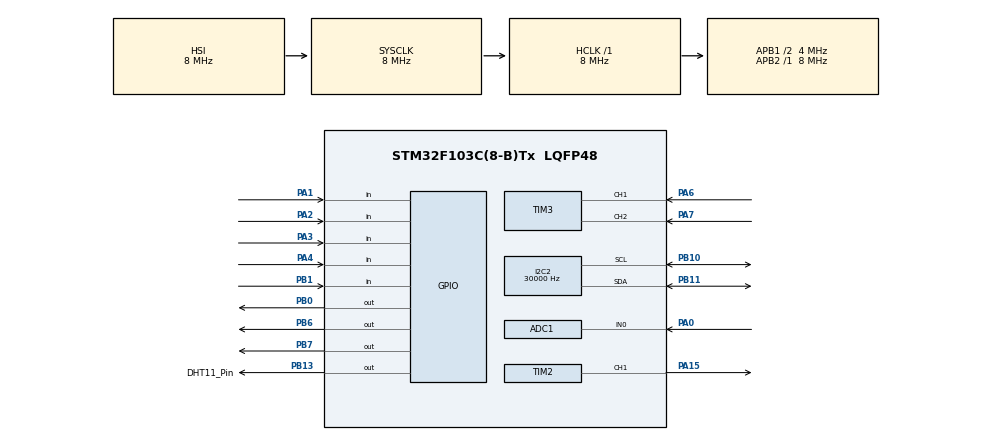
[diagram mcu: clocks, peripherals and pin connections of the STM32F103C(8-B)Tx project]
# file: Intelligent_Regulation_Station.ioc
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ADC1.Channel-2\#ChannelRegularConversion=ADC_CHANNEL_0
ADC1.EnableInjectedConversion=ENABLE
ADC1.InjNumberOfConversion=0
ADC1.NbrOfConversion=1
ADC1.NbrOfConversionFlag=1
ADC1.Rank-2\#ChannelRegularConversion=1
ADC1.SamplingTime-2\#ChannelRegularConversion=ADC_SAMPLETIME_1CYCLE_5
ADC1.master=1
FREERTOS.Tasks01=OLED_Task,8,512,Start_OLED_Task,As weak,NULL,Dynamic,NULL,NULL;air_sensor_Task,16,384,Start_air_sensor_Task,As weak,NULL,Dynamic,NULL,NULL;dht11_Task,16,384,Start_dht_Task,As weak,NULL,Dynamic,NULL,NULL;key_Task,40,256,Start_key_Task,As weak,NULL,Dynamic,NULL,NULL;encoder_Task,32,256,Start_encoder_Task,As weak,NULL,Dynamic,NULL,NULL;Battery_Task,8,256,Start_Battery_Task,As weak,NULL,Dynamic,NULL,NULL
FREERTOS.configTOTAL_HEAP_SIZE=12288
I2C2.ClockSpeed=30000
Mcu.Family=STM32F1
Mcu.Name=STM32F103C(8-B)Tx
Mcu.Package=LQFP48
NVIC.PriorityGroup=NVIC_PRIORITYGROUP_4
NVIC.TIM1_UP_IRQn=true\:15\:0\:false\:false\:true\:false\:false\:true\:true
NVIC.TimeBase=TIM1_UP_IRQn
NVIC.TimeBaseIP=TIM1
PA0-WKUP.GPIO_Mode=GPIO_MODE_ANALOG
PA0-WKUP.Signal=SharedAnalog_PA0
PA1.GPIO_Mode=GPIO_MODE_INPUT
PA1.GPIO_PuPd=GPIO_PULLUP
PA1.Signal=GPIO_Input
PA13.Mode=Serial_Wire
PA13.Signal=SYS_JTMS-SWDIO
PA14.Mode=Serial_Wire
PA14.Signal=SYS_JTCK-SWCLK
PA15.Signal=S_TIM2_CH1_ETR
PA2.GPIO_Mode=GPIO_MODE_INPUT
PA2.GPIO_PuPd=GPIO_PULLUP
PA2.Signal=GPIO_Input
PA3.GPIO_Mode=GPIO_MODE_INPUT
PA3.GPIO_PuPd=GPIO_PULLUP
PA3.Signal=GPIO_Input
PA4.GPIO_Mode=GPIO_MODE_INPUT
PA4.GPIO_PuPd=GPIO_PULLUP
PA4.Signal=GPIO_Input
PA6.Signal=S_TIM3_CH1
PA7.Signal=S_TIM3_CH2
PB0.Signal=GPIO_Output
PB1.GPIO_PuPd=GPIO_PULLUP
PB1.Signal=GPIO_Input
PB10.Mode=I2C
PB10.Signal=I2C2_SCL
PB11.Mode=I2C
PB11.Signal=I2C2_SDA
PB13.GPIO_Label=DHT11_Pin
PB13.GPIO_ModeDefaultOutputPP=GPIO_MODE_OUTPUT_PP
PB13.GPIO_PuPd=GPIO_NOPULL
PB13.Signal=GPIO_Output
PB6.PinState=GPIO_PIN_RESET
PB6.Signal=GPIO_Output
PB7.PinState=GPIO_PIN_RESET
PB7.Signal=GPIO_Output
PD0-OSC_IN.Mode=HSE-External-Oscillator
PD0-OSC_IN.Signal=RCC_OSC_IN
PD1-OSC_OUT.Mode=HSE-External-Oscillator
PD1-OSC_OUT.Signal=RCC_OSC_OUT
ProjectManager.HeapSize=0x200
ProjectManager.StackSize=0x400
ProjectManager.TargetToolchain=CMake
RCC.ADCPresc=RCC_ADCPCLK2_DIV6
RCC.AHBFreq_Value=8000000
RCC.APB1CLKDivider=RCC_HCLK_DIV2
RCC.APB1Freq_Value=4000000
RCC.APB1TimFreq_Value=8000000
RCC.APB2Freq_Value=8000000
RCC.APB2TimFreq_Value=8000000
RCC.HCLKFreq_Value=8000000
RCC.PLLMUL=RCC_PLL_MUL9
RCC.SYSCLKFreq_VALUE=8000000
RCC.USBFreq_Value=36000000
SH.S_TIM2_CH1_ETR.0=TIM2_CH1,PWM Generation1 CH1
SH.S_TIM3_CH1.0=TIM3_CH1,Encoder_Interface
SH.S_TIM3_CH2.0=TIM3_CH2,Encoder_Interface
SH.SharedAnalog_PA0.0=GPIO_Analog
SH.SharedAnalog_PA0.1=ADC1_IN0,IN0
TIM2.AutoReloadPreload=TIM_AUTORELOAD_PRELOAD_ENABLE
TIM2.Channel-PWM\ Generation1\ CH1=TIM_CHANNEL_1
TIM2.Period=999
TIM2.Prescaler=71
TIM3.AutoReloadPreload=TIM_AUTORELOAD_PRELOAD_ENABLE
TIM3.EncoderMode=TIM_ENCODERMODE_TI12
TIM4.Prescaler=71
VP_FREERTOS_VS_CMSIS_V2.Mode=CMSIS_V2
VP_SYS_VS_tim1.Mode=TIM1
VP_TIM2_VS_ClockSourceINT.Mode=Internal
VP_TIM4_VS_ClockSourceINT.Mode=Internal
board=custom

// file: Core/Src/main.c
/* USER CODE BEGIN Header */
/**
  ******************************************************************************
  * @file           : main.c
  * @brief          : Main program body
  ******************************************************************************
  * @attention
  *
  * Copyright (c) 2026 STMicroelectronics.
  * All rights reserved.
  *
  * This software is licensed under terms that can be found in the LICENSE file
  * in the root directory of this software component.
  * If no LICENSE file comes with this software, it is provided AS-IS.
  *
  ******************************************************************************
  */
/* USER CODE END Header */
#include "main.h"
#include "cmsis_os.h"

ADC_HandleTypeDef hadc1;

I2C_HandleTypeDef hi2c2;

TIM_HandleTypeDef htim2;
TIM_HandleTypeDef htim3;
TIM_HandleTypeDef htim4;

/* Definitions for OLED_Task */
osThreadId_t OLED_TaskHandle;
const osThreadAttr_t OLED_Task_attributes = {
  .name = "OLED_Task",
  .stack_size = 512 * 4,
  .priority = (osPriority_t) osPriorityLow,
};
/* Definitions for air_sensor_Task */
osThreadId_t air_sensor_TaskHandle;
const osThreadAttr_t air_sensor_Task_attributes = {
  .name = "air_sensor_Task",
  .stack_size = 384 * 4,
  .priority = (osPriority_t) osPriorityBelowNormal,
};
/* Definitions for dht11_Task */
osThreadId_t dht11_TaskHandle;
const osThreadAttr_t dht11_Task_attributes = {
  .name = "dht11_Task",
  .stack_size = 384 * 4,
  .priority = (osPriority_t) osPriorityBelowNormal,
};
/* Definitions for key_Task */
osThreadId_t key_TaskHandle;
const osThreadAttr_t key_Task_attributes = {
  .name = "key_Task",
  .stack_size = 256 * 4,
  .priority = (osPriority_t) osPriorityHigh,
};
/* Definitions for encoder_Task */
osThreadId_t encoder_TaskHandle;
const osThreadAttr_t encoder_Task_attributes = {
  .name = "encoder_Task",
  .stack_size = 256 * 4,
  .priority = (osPriority_t) osPriorityAboveNormal,
};
/* Definitions for Battery_Task */
osThreadId_t Battery_TaskHandle;
const osThreadAttr_t Battery_Task_attributes = {
  .name = "Battery_Task",
  .stack_size = 256 * 4,
  .priority = (osPriority_t) osPriorityLow,
};

void SystemClock_Config(void);
static void MX_GPIO_Init(void);
static void MX_ADC1_Init(void);
static void MX_I2C2_Init(void);
static void MX_TIM2_Init(void);
static void MX_TIM3_Init(void);
static void MX_TIM4_Init(void);
void Start_OLED_Task(void *argument);
void Start_air_sensor_Task(void *argument);
void Start_dht_Task(void *argument);
void Start_key_Task(void *argument);
void Start_encoder_Task(void *argument);
void Start_Battery_Task(void *argument);

int main(void)
{

  /* MCU Configuration--------------------------------------------------------*/

  /* Reset of all peripherals, Initializes the Flash interface and the Systick. */
  HAL_Init();

  /* Configure the system clock */
  SystemClock_Config();

  /* Initialize all configured peripherals */
  MX_GPIO_Init();
  MX_ADC1_Init();
  MX_I2C2_Init();
  MX_TIM2_Init();
  MX_TIM3_Init();
  MX_TIM4_Init();

  /* Init scheduler */
  osKernelInitialize();

  /* Create the thread(s) */
  /* creation of OLED_Task */
  OLED_TaskHandle = osThreadNew(Start_OLED_Task, NULL, &OLED_Task_attributes);

  /* creation of air_sensor_Task */
  air_sensor_TaskHandle = osThreadNew(Start_air_sensor_Task, NULL, &air_sensor_Task_attributes);

  /* creation of dht11_Task */
  dht11_TaskHandle = osThreadNew(Start_dht_Task, NULL, &dht11_Task_attributes);

  /* creation of key_Task */
  key_TaskHandle = osThreadNew(Start_key_Task, NULL, &key_Task_attributes);

  /* creation of encoder_Task */
  encoder_TaskHandle = osThreadNew(Start_encoder_Task, NULL, &encoder_Task_attributes);

  /* creation of Battery_Task */
  Battery_TaskHandle = osThreadNew(Start_Battery_Task, NULL, &Battery_Task_attributes);

  /* Start scheduler */
  osKernelStart();

  /* We should never get here as control is now taken by the scheduler */

  /* Infinite loop */
  while (1)
  {

  }
}

void SystemClock_Config(void)
{
  RCC_OscInitTypeDef RCC_OscInitStruct = {0};
  RCC_ClkInitTypeDef RCC_ClkInitStruct = {0};
  RCC_PeriphCLKInitTypeDef PeriphClkInit = {0};

  /** Initializes the RCC Oscillators according to the specified parameters
  * in the RCC_OscInitTypeDef structure.
  */
  RCC_OscInitStruct.OscillatorType = RCC_OSCILLATORTYPE_HSI;
  RCC_OscInitStruct.HSIState = RCC_HSI_ON;
  RCC_OscInitStruct.HSICalibrationValue = RCC_HSICALIBRATION_DEFAULT;
  RCC_OscInitStruct.PLL.PLLState = RCC_PLL_NONE;
  if (HAL_RCC_OscConfig(&RCC_OscInitStruct) != HAL_OK)
  {
    Error_Handler();
  }

  /** Initializes the CPU, AHB and APB buses clocks
  */
  RCC_ClkInitStruct.ClockType = RCC_CLOCKTYPE_HCLK|RCC_CLOCKTYPE_SYSCLK
                              |RCC_CLOCKTYPE_PCLK1|RCC_CLOCKTYPE_PCLK2;
  RCC_ClkInitStruct.SYSCLKSource = RCC_SYSCLKSOURCE_HSI;
  RCC_ClkInitStruct.AHBCLKDivider = RCC_SYSCLK_DIV1;
  RCC_ClkInitStruct.APB1CLKDivider = RCC_HCLK_DIV2;
  RCC_ClkInitStruct.APB2CLKDivider = RCC_HCLK_DIV1;

  if (HAL_RCC_ClockConfig(&RCC_ClkInitStruct, FLASH_LATENCY_0) != HAL_OK)
  {
    Error_Handler();
  }
  PeriphClkInit.PeriphClockSelection = RCC_PERIPHCLK_ADC;
  PeriphClkInit.AdcClockSelection = RCC_ADCPCLK2_DIV6;
  if (HAL_RCCEx_PeriphCLKConfig(&PeriphClkInit) != HAL_OK)
  {
    Error_Handler();
  }
}

static void MX_ADC1_Init(void)
{

  ADC_ChannelConfTypeDef sConfig = {0};

  /* USER CODE BEGIN ADC1_Init 1 */
  __HAL_RCC_ADC1_CLK_ENABLE();
  /* USER CODE END ADC1_Init 1 */

  /** Common config
  */
  hadc1.Instance = ADC1;
  hadc1.Init.ScanConvMode = ADC_SCAN_DISABLE;
  hadc1.Init.ContinuousConvMode = DISABLE;
  hadc1.Init.DiscontinuousConvMode = DISABLE;
  hadc1.Init.ExternalTrigConv = ADC_SOFTWARE_START;
  hadc1.Init.DataAlign = ADC_DATAALIGN_RIGHT;
  hadc1.Init.NbrOfConversion = 1;
  if (HAL_ADC_Init(&hadc1) != HAL_OK)
  {
    Error_Handler();
  }

  /** Configure Regular Channel
  */
  sConfig.Channel = ADC_CHANNEL_0;
  sConfig.Rank = ADC_REGULAR_RANK_1;
  sConfig.SamplingTime = ADC_SAMPLETIME_239CYCLES_5;
  if (HAL_ADC_ConfigChannel(&hadc1, &sConfig) != HAL_OK)
  {
    Error_Handler();
  }
  /* USER CODE BEGIN ADC1_Init 2 */
  HAL_ADCEx_Calibration_Start(&hadc1);
  /* USER CODE END ADC1_Init 2 */

}

static void MX_I2C2_Init(void)
{

  hi2c2.Instance = I2C2;
  hi2c2.Init.ClockSpeed = 30000;
  hi2c2.Init.DutyCycle = I2C_DUTYCYCLE_2;
  hi2c2.Init.OwnAddress1 = 0;
  hi2c2.Init.AddressingMode = I2C_ADDRESSINGMODE_7BIT;
  hi2c2.Init.DualAddressMode = I2C_DUALADDRESS_DISABLE;
  hi2c2.Init.OwnAddress2 = 0;
  hi2c2.Init.GeneralCallMode = I2C_GENERALCALL_DISABLE;
  hi2c2.Init.NoStretchMode = I2C_NOSTRETCH_DISABLE;
  if (HAL_I2C_Init(&hi2c2) != HAL_OK)
  {
    Error_Handler();
  }

}

static void MX_TIM2_Init(void)
{

  TIM_ClockConfigTypeDef sClockSourceConfig = {0};
  TIM_MasterConfigTypeDef sMasterConfig = {0};
  TIM_OC_InitTypeDef sConfigOC = {0};

  htim2.Instance = TIM2;
  htim2.Init.Prescaler = 71;
  htim2.Init.CounterMode = TIM_COUNTERMODE_UP;
  htim2.Init.Period = 999;
  htim2.Init.ClockDivision = TIM_CLOCKDIVISION_DIV1;
  htim2.Init.AutoReloadPreload = TIM_AUTORELOAD_PRELOAD_ENABLE;
  if (HAL_TIM_Base_Init(&htim2) != HAL_OK)
  {
    Error_Handler();
  }
  sClockSourceConfig.ClockSource = TIM_CLOCKSOURCE_INTERNAL;
  if (HAL_TIM_ConfigClockSource(&htim2, &sClockSourceConfig) != HAL_OK)
  {
    Error_Handler();
  }
  if (HAL_TIM_PWM_Init(&htim2) != HAL_OK)
  {
    Error_Handler();
  }
  sMasterConfig.MasterOutputTrigger = TIM_TRGO_RESET;
  sMasterConfig.MasterSlaveMode = TIM_MASTERSLAVEMODE_DISABLE;
  if (HAL_TIMEx_MasterConfigSynchronization(&htim2, &sMasterConfig) != HAL_OK)
  {
    Error_Handler();
  }
  sConfigOC.OCMode = TIM_OCMODE_PWM1;
  sConfigOC.Pulse = 0;
  sConfigOC.OCPolarity = TIM_OCPOLARITY_HIGH;
  sConfigOC.OCFastMode = TIM_OCFAST_DISABLE;
  if (HAL_TIM_PWM_ConfigChannel(&htim2, &sConfigOC, TIM_CHANNEL_1) != HAL_OK)
  {
    Error_Handler();
  }
  HAL_TIM_MspPostInit(&htim2);

}

static void MX_TIM3_Init(void)
{

  TIM_Encoder_InitTypeDef sConfig = {0};
  TIM_MasterConfigTypeDef sMasterConfig = {0};

  htim3.Instance = TIM3;
  htim3.Init.Prescaler = 0;
  htim3.Init.CounterMode = TIM_COUNTERMODE_UP;
  htim3.Init.Period = 65535;
  htim3.Init.ClockDivision = TIM_CLOCKDIVISION_DIV1;
  htim3.Init.AutoReloadPreload = TIM_AUTORELOAD_PRELOAD_ENABLE;
  sConfig.EncoderMode = TIM_ENCODERMODE_TI12;
  sConfig.IC1Polarity = TIM_ICPOLARITY_RISING;
  sConfig.IC1Selection = TIM_ICSELECTION_DIRECTTI;
  sConfig.IC1Prescaler = TIM_ICPSC_DIV1;
  sConfig.IC1Filter = 0;
  sConfig.IC2Polarity = TIM_ICPOLARITY_RISING;
  sConfig.IC2Selection = TIM_ICSELECTION_DIRECTTI;
  sConfig.IC2Prescaler = TIM_ICPSC_DIV1;
  sConfig.IC2Filter = 0;
  if (HAL_TIM_Encoder_Init(&htim3, &sConfig) != HAL_OK)
  {
    Error_Handler();
  }
  sMasterConfig.MasterOutputTrigger = TIM_TRGO_RESET;
  sMasterConfig.MasterSlaveMode = TIM_MASTERSLAVEMODE_DISABLE;
  if (HAL_TIMEx_MasterConfigSynchronization(&htim3, &sMasterConfig) != HAL_OK)
  {
    Error_Handler();
  }

}

static void MX_TIM4_Init(void)
{

  TIM_ClockConfigTypeDef sClockSourceConfig = {0};
  TIM_MasterConfigTypeDef sMasterConfig = {0};

  htim4.Instance = TIM4;
  htim4.Init.Prescaler = 71;
  htim4.Init.CounterMode = TIM_COUNTERMODE_UP;
  htim4.Init.Period = 65535;
  htim4.Init.ClockDivision = TIM_CLOCKDIVISION_DIV1;
  htim4.Init.AutoReloadPreload = TIM_AUTORELOAD_PRELOAD_DISABLE;
  if (HAL_TIM_Base_Init(&htim4) != HAL_OK)
  {
    Error_Handler();
  }
  sClockSourceConfig.ClockSource = TIM_CLOCKSOURCE_INTERNAL;
  if (HAL_TIM_ConfigClockSource(&htim4, &sClockSourceConfig) != HAL_OK)
  {
    Error_Handler();
  }
  sMasterConfig.MasterOutputTrigger = TIM_TRGO_RESET;
  sMasterConfig.MasterSlaveMode = TIM_MASTERSLAVEMODE_DISABLE;
  if (HAL_TIMEx_MasterConfigSynchronization(&htim4, &sMasterConfig) != HAL_OK)
  {
    Error_Handler();
  }

}

static void MX_GPIO_Init(void)
{
  GPIO_InitTypeDef GPIO_InitStruct = {0};

  /* GPIO Ports Clock Enable */
  __HAL_RCC_GPIOD_CLK_ENABLE();
  __HAL_RCC_GPIOA_CLK_ENABLE();
  __HAL_RCC_GPIOB_CLK_ENABLE();

  /*Configure GPIO pin Output Level */
  HAL_GPIO_WritePin(GPIOB, GPIO_PIN_0|DHT11_Pin_Pin|GPIO_PIN_6|GPIO_PIN_7, GPIO_PIN_RESET);

  /*Configure GPIO pins : PA1 PA2 PA3 PA4 */
  GPIO_InitStruct.Pin = GPIO_PIN_1|GPIO_PIN_2|GPIO_PIN_3|GPIO_PIN_4;
  GPIO_InitStruct.Mode = GPIO_MODE_INPUT;
  GPIO_InitStruct.Pull = GPIO_PULLUP;
  HAL_GPIO_Init(GPIOA, &GPIO_InitStruct);

  /*Configure GPIO pins : PB0 DHT11_Pin_Pin PB6 PB7 */
  GPIO_InitStruct.Pin = GPIO_PIN_0|DHT11_Pin_Pin|GPIO_PIN_6|GPIO_PIN_7;
  GPIO_InitStruct.Mode = GPIO_MODE_OUTPUT_PP;
  GPIO_InitStruct.Pull = GPIO_NOPULL;
  GPIO_InitStruct.Speed = GPIO_SPEED_FREQ_LOW;
  HAL_GPIO_Init(GPIOB, &GPIO_InitStruct);

  /*Configure GPIO pin : PB1 */
  GPIO_InitStruct.Pin = GPIO_PIN_1;
  GPIO_InitStruct.Mode = GPIO_MODE_INPUT;
  GPIO_InitStruct.Pull = GPIO_PULLUP;
  HAL_GPIO_Init(GPIOB, &GPIO_InitStruct);

}

__weak void Start_OLED_Task(void *argument)
{
  for(;;)
  {
    osDelay(1);
  }
}

__weak void Start_air_sensor_Task(void *argument)
{
  for(;;)
  {
    osDelay(1);
  }
}

__weak void Start_dht_Task(void *argument)
{
  for(;;)
  {
    osDelay(1);
  }
}

__weak void Start_key_Task(void *argument)
{
  for(;;)
  {
    osDelay(1);
  }
}

__weak void Start_encoder_Task(void *argument)
{
  for(;;)
  {
    osDelay(1);
  }
}

__weak void Start_Battery_Task(void *argument)
{
  for(;;)
  {
    osDelay(1);
  }
}

void HAL_TIM_PeriodElapsedCallback(TIM_HandleTypeDef *htim)
{
  if (htim->Instance == TIM1)
  {
    HAL_IncTick();
  }
}

void Error_Handler(void)
{
  __disable_irq();
  while (1)
  {
  }
}
